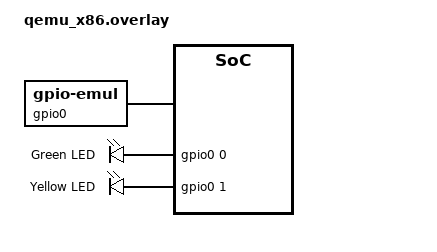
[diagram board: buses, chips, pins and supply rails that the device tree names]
#include <zephyr/dt-bindings/gpio/gpio.h>

/ {  
	gpio0: gpio_emul {
		status = "okay";
		compatible = "zephyr,gpio-emul";
		rising-edge;
		falling-edge;
		high-level;
		low-level;
		gpio-controller;
		#gpio-cells = <2>;
	};

  leds {
		compatible = "gpio-leds";
		led0: led_0 {
			gpios = <&gpio0 0 GPIO_ACTIVE_HIGH>;
			label = "Green LED";
		};
    led1: led_1 {
			gpios = <&gpio0 1 GPIO_ACTIVE_HIGH>;
			label = "Yellow LED";
		};
	};

  aliases {
    led0 = &led0;
		led1 = &led1;
	};
};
